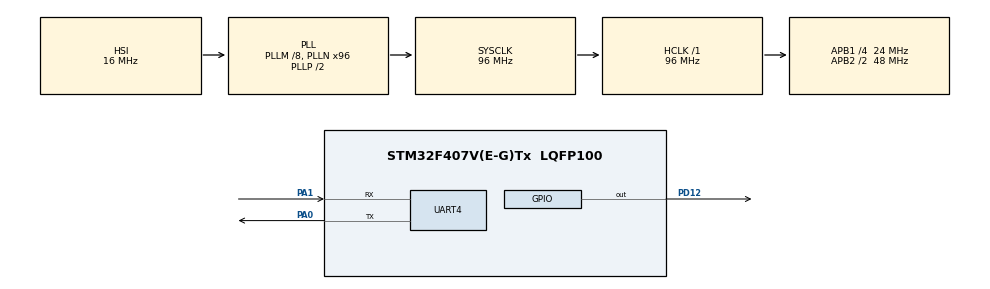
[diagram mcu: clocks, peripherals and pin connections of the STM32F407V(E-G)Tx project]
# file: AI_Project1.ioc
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Mcu.Family=STM32F4
Mcu.Name=STM32F407V(E-G)Tx
Mcu.Package=LQFP100
NVIC.PriorityGroup=NVIC_PRIORITYGROUP_4
PA0-WKUP.Mode=Asynchronous
PA0-WKUP.Signal=UART4_TX
PA1.Mode=Asynchronous
PA1.Signal=UART4_RX
PA13.Mode=Serial_Wire
PA13.Signal=SYS_JTMS-SWDIO
PA14.Mode=Serial_Wire
PA14.Signal=SYS_JTCK-SWCLK
PD12.Signal=GPIO_Output
ProjectManager.HeapSize=0x800
ProjectManager.StackSize=0x800
ProjectManager.TargetToolchain=STM32CubeIDE
RCC.48MHZClocksFreq_Value=48000000
RCC.AHBFreq_Value=96000000
RCC.APB1CLKDivider=RCC_HCLK_DIV4
RCC.APB1Freq_Value=24000000
RCC.APB1TimFreq_Value=48000000
RCC.APB2CLKDivider=RCC_HCLK_DIV2
RCC.APB2Freq_Value=48000000
RCC.APB2TimFreq_Value=96000000
RCC.CortexFreq_Value=96000000
RCC.HCLKFreq_Value=96000000
RCC.HSE_VALUE=25000000
RCC.HSI_VALUE=16000000
RCC.LSE_VALUE=32768
RCC.PLLM=8
RCC.PLLN=96
RCC.SYSCLKFreq_VALUE=96000000
RCC.SYSCLKSource=RCC_SYSCLKSOURCE_PLLCLK
RCC.VCOOutputFreq_Value=192000000
STMicroelectronics.X-CUBE-AI.10.2.0.ActivationBufferSizeList=2084
STMicroelectronics.X-CUBE-AI.10.2.0.ActivationBuffers=pool0
STMicroelectronics.X-CUBE-AI.10.2.0.ActivationNames=pool0
STMicroelectronics.X-CUBE-AI.10.2.0.ActivationSizes=AI_TEMP_CLASSIFIER_DATA_ACTIVATION_1_SIZE
STMicroelectronics.X-CUBE-AI.10.2.0.HeapSize=0x800
STMicroelectronics.X-CUBE-AI.10.2.0.InternalRamActivationBufferMaxSize=AI_TEMP_CLASSIFIER_DATA_ACTIVATIONS_SIZE
STMicroelectronics.X-CUBE-AI.10.2.0.LatestDirectoryUsed-0a6a85d186a75581f6178683ed5afddc2fad123f2e5eddf822d37d77b35d761b=C\:\\Users\\z665059\\OneDrive - ZF Friedrichshafen AG\\Documents\\my_project_temperature_classification\\notebooks
STMicroelectronics.X-CUBE-AI.10.2.0.MaximumNumberOfInputLayer=1
STMicroelectronics.X-CUBE-AI.10.2.0.MaximumNumberOfOutputLayer=1
STMicroelectronics.X-CUBE-AI.10.2.0.MaximumSizeOfInputLayer=1
STMicroelectronics.X-CUBE-AI.10.2.0.MaximumSizeOfOutputLayer=1
STMicroelectronics.X-CUBE-AI.10.2.0.ModelActualCompression-0a6a85d186a75581f6178683ed5afddc2fad123f2e5eddf822d37d77b35d761b=0.0
STMicroelectronics.X-CUBE-AI.10.2.0.ModelCompression-0a6a85d186a75581f6178683ed5afddc2fad123f2e5eddf822d37d77b35d761b=None
STMicroelectronics.X-CUBE-AI.10.2.0.ModelFlashOccupation-0a6a85d186a75581f6178683ed5afddc2fad123f2e5eddf822d37d77b35d761b=11472
STMicroelectronics.X-CUBE-AI.10.2.0.ModelHashList=0a6a85d186a75581f6178683ed5afddc2fad123f2e5eddf822d37d77b35d761b
STMicroelectronics.X-CUBE-AI.10.2.0.ModelKind-0a6a85d186a75581f6178683ed5afddc2fad123f2e5eddf822d37d77b35d761b=TFLITE
STMicroelectronics.X-CUBE-AI.10.2.0.ModelMacc-0a6a85d186a75581f6178683ed5afddc2fad123f2e5eddf822d37d77b35d761b=264
STMicroelectronics.X-CUBE-AI.10.2.0.ModelName-0a6a85d186a75581f6178683ed5afddc2fad123f2e5eddf822d37d77b35d761b=temp_classifier
STMicroelectronics.X-CUBE-AI.10.2.0.ModelNameList=temp_classifier
STMicroelectronics.X-CUBE-AI.10.2.0.ModelRamOccupation-0a6a85d186a75581f6178683ed5afddc2fad123f2e5eddf822d37d77b35d761b=2084
STMicroelectronics.X-CUBE-AI.10.2.0.ModelStructureFile-0a6a85d186a75581f6178683ed5afddc2fad123f2e5eddf822d37d77b35d761b=/C\:/Users/z665059/OneDrive - ZF Friedrichshafen AG/Documents/my_project_temperature_classification/notebooks/dht22_temp_classifier.tflite
STMicroelectronics.X-CUBE-AI.10.2.0.ModelType-0a6a85d186a75581f6178683ed5afddc2fad123f2e5eddf822d37d77b35d761b=STM32Cube.AI MCU runtime
STMicroelectronics.X-CUBE-AI.10.2.0.ReadyForCodeGeneration=true
STMicroelectronics.X-CUBE-AI.10.2.0.StackSize=0x800
STMicroelectronics.X-CUBE-AI.10.2.0.WorkingBufferStartAddrList=0xFFFFFFFF
STMicroelectronics.X-CUBE-AI.10.2.0.XAaCUBEAaAICcArtificialOoIntelligenceJjCore=true
STMicroelectronics.X-CUBE-AI.10.2.0.copyWeightToRam=false
STMicroelectronics.X-CUBE-AI.10.2.0.copyWeightToRam-0a6a85d186a75581f6178683ed5afddc2fad123f2e5eddf822d37d77b35d761b=false
STMicroelectronics.X-CUBE-AI.10.2.0.customLayerConfigEnabled=false
STMicroelectronics.X-CUBE-AI.10.2.0.customLayerConfigEnabled-0a6a85d186a75581f6178683ed5afddc2fad123f2e5eddf822d37d77b35d761b=false
STMicroelectronics.X-CUBE-AI.10.2.0.noOnnxIoTranspose=false
STMicroelectronics.X-CUBE-AI.10.2.0.noOnnxIoTranspose-0a6a85d186a75581f6178683ed5afddc2fad123f2e5eddf822d37d77b35d761b=false
STMicroelectronics.X-CUBE-AI.10.2.0.useInputAllocation=true
STMicroelectronics.X-CUBE-AI.10.2.0.useInputAllocation-0a6a85d186a75581f6178683ed5afddc2fad123f2e5eddf822d37d77b35d761b=true
STMicroelectronics.X-CUBE-AI.10.2.0.useOutputAllocation=true
STMicroelectronics.X-CUBE-AI.10.2.0.useOutputAllocation-0a6a85d186a75581f6178683ed5afddc2fad123f2e5eddf822d37d77b35d761b=true
TIM2.Period=65536
TIM2.Prescaler=96
UART4.VirtualMode=Asynchronous
VP_CRC_VS_CRC.Mode=CRC_Activate
VP_STMicroelectronics.X-CUBE-AI_VS_ArtificialOoIntelligenceJjXAaCUBEAaAI_10.2.0.Mode=ArtificialOoIntelligenceJjXAaCUBEAaAI
VP_TIM2_VS_ClockSourceINT.Mode=Internal
board=custom

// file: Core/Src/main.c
/* USER CODE BEGIN Header */
/**
  ******************************************************************************
  * @file           : main.c
  * @brief          : Main program body
  ******************************************************************************
  * @attention
  *
  * Copyright (c) 2026 STMicroelectronics.
  * All rights reserved.
  *
  * This software is licensed under terms that can be found in the LICENSE file
  * in the root directory of this software component.
  * If no LICENSE file comes with this software, it is provided AS-IS.
  *
  ******************************************************************************
  */
/* USER CODE END Header */
#include "main.h"

/* USER CODE BEGIN Includes */
#include <stdio.h>
#include <stdlib.h>
#include <time.h>
#include <string.h>

#include "ai_datatypes_defines.h"
#include "ai_platform.h"
#include "temp_classifier.h"
#include "temp_classifier_data.h"
/* USER CODE END Includes */

CRC_HandleTypeDef hcrc;

TIM_HandleTypeDef htim2;

UART_HandleTypeDef huart4;

/* USER CODE BEGIN PV */
/**
 * @brief Statically allocated buffers.
 * Buffers can be dynamically allocated using malloc and size information
 * given by the report in ai_network_get_report().
 */
// Chunk of memory used to hold intermediate values for neural network
ai_u8 activations[AI_TEMP_CLASSIFIER_DATA_ACTIVATIONS_SIZE];
// Buffers used to store input and output tensors
ai_u8 in_data[AI_TEMP_CLASSIFIER_IN_1_SIZE_BYTES];
ai_u8 out_data[AI_TEMP_CLASSIFIER_OUT_1_SIZE_BYTES];

/* AI buffer IO handlers */
// Initialize wrapper structs that hold pointers to data and info about the
  // data (tensor height, width, channels)
ai_buffer *ai_input;
ai_buffer *ai_output;
/* USER CODE END PV */

void SystemClock_Config(void);
static void MX_GPIO_Init(void);
static void MX_CRC_Init(void);
static void MX_TIM2_Init(void);
static void MX_UART4_Init(void);

int main(void)
{

  /* USER CODE BEGIN 1 */
	// Pointer to our model
	ai_handle temp_classifier = AI_HANDLE_NULL; //update network name from report
	ai_error err;
	ai_network_report report;
	//char buf[50];
	//int buf_len = 0;
	ai_i32 nbatch;
	uint32_t timestamp;
	float y_val;
	float temp_c = 15.0; //dht22_read_temperature();
	float temp_norm = temp_c / 50.0f;

  /* USER CODE END 1 */

  /* MCU Configuration--------------------------------------------------------*/

  /* Reset of all peripherals, Initializes the Flash interface and the Systick. */
  HAL_Init();

  /* Configure the system clock */
  SystemClock_Config();

  /* Initialize all configured peripherals */
  MX_GPIO_Init();
  MX_CRC_Init();
  MX_TIM2_Init();
  MX_UART4_Init();
  /* USER CODE BEGIN 2 */
  // Greetings!
     printf("\r\n\r\nSTM32 X-Cube-AI test\r\n");

  /** @brief Initialize network */
      const ai_handle acts[] = { activations };
      err = ai_temp_classifier_create_and_init(&temp_classifier, acts, NULL);
      if (err.type != AI_ERROR_NONE) {
          printf("ai init_and_create error\n");
          return -1;
      }

  /** @brief {optional} for debug/log purpose */
	  if (ai_temp_classifier_get_report(temp_classifier, &report) != true) {
		  printf("ai get report error\n");
		  return -1;
	  }

	  printf("Model name      : %s\n", report.model_name);
	  printf("Model signature : %s\n", report.model_signature);

	  ai_input = &report.inputs[0];
	  ai_output = &report.outputs[0];
	  printf("input[0] : (%ld, %ld, %ld)\n", AI_BUFFER_SHAPE_ELEM(ai_input, AI_SHAPE_HEIGHT),
										  AI_BUFFER_SHAPE_ELEM(ai_input, AI_SHAPE_WIDTH),
										  AI_BUFFER_SHAPE_ELEM(ai_input, AI_SHAPE_CHANNEL));
	  printf("output[0] : (%ld, %ld, %ld)\n", AI_BUFFER_SHAPE_ELEM(ai_output, AI_SHAPE_HEIGHT),
										   AI_BUFFER_SHAPE_ELEM(ai_output, AI_SHAPE_WIDTH),
										   AI_BUFFER_SHAPE_ELEM(ai_output, AI_SHAPE_CHANNEL));

	  // Set pointers wrapper structs to our data buffers
	  //ai_input[0].n_batches = 1; //n_batches = number of input samples processed in one inference call
	  //if >1    Process multiple samples together
	  ai_input[0].data = AI_HANDLE_PTR(in_data);
	  //ai_output[0].n_batches = 1;
	  ai_output[0].data = AI_HANDLE_PTR(out_data);

	  // Start timer/counter
	    HAL_TIM_Base_Start(&htim2);

  /* USER CODE END 2 */

  /* Infinite loop */
  /* USER CODE BEGIN WHILE */
  while (1)
  {
	/* Copy normalized value to AI input buffer */
	((ai_float *)in_data)[0] = (ai_float)temp_norm;

	// Get current timestamp
	 timestamp = htim2.Instance->CNT;

	 // Perform inference
	 nbatch = ai_temp_classifier_run(temp_classifier, &ai_input[0], &ai_output[0]);
	 if (nbatch != 1) {
		 err = ai_temp_classifier_get_error(temp_classifier);
		 printf("ai run error %d, %d\n", err.type, err.code);
		 return -1;
		 //buf_len = sprintf(buf, "Error: could not run inference\r\n");
		 //HAL_UART_Transmit(&huart4, (uint8_t *)buf, buf_len, 100);
	 }

	 /** @brief Post-process the output results/predictions */
	     printf("Inference output..\n");
	     for (int i = 0; i < AI_TEMP_CLASSIFIER_OUT_1_SIZE; i++) {
	         printf("%d,", out_data[i]);
	     }
	     printf("\n");
	     // Read output (predicted y) of neural network
	     y_val = ((float *)out_data)[0];

	     // Print output of neural network along with inference time (microseconds)
	     printf("Output: %f | Duration: %lu\r\n",y_val,htim2.Instance->CNT - timestamp);

	     // Wait before doing it again
	     HAL_Delay(500);

    /* USER CODE END WHILE */

  }
}

void SystemClock_Config(void)
{
  RCC_OscInitTypeDef RCC_OscInitStruct = {0};
  RCC_ClkInitTypeDef RCC_ClkInitStruct = {0};

  /** Configure the main internal regulator output voltage
  */
  __HAL_RCC_PWR_CLK_ENABLE();
  __HAL_PWR_VOLTAGESCALING_CONFIG(PWR_REGULATOR_VOLTAGE_SCALE1);

  /** Initializes the RCC Oscillators according to the specified parameters
  * in the RCC_OscInitTypeDef structure.
  */
  RCC_OscInitStruct.OscillatorType = RCC_OSCILLATORTYPE_HSI;
  RCC_OscInitStruct.HSIState = RCC_HSI_ON;
  RCC_OscInitStruct.HSICalibrationValue = RCC_HSICALIBRATION_DEFAULT;
  RCC_OscInitStruct.PLL.PLLState = RCC_PLL_ON;
  RCC_OscInitStruct.PLL.PLLSource = RCC_PLLSOURCE_HSI;
  RCC_OscInitStruct.PLL.PLLM = 8;
  RCC_OscInitStruct.PLL.PLLN = 96;
  RCC_OscInitStruct.PLL.PLLP = RCC_PLLP_DIV2;
  RCC_OscInitStruct.PLL.PLLQ = 4;
  if (HAL_RCC_OscConfig(&RCC_OscInitStruct) != HAL_OK)
  {
    Error_Handler();
  }

  /** Initializes the CPU, AHB and APB buses clocks
  */
  RCC_ClkInitStruct.ClockType = RCC_CLOCKTYPE_HCLK|RCC_CLOCKTYPE_SYSCLK
                              |RCC_CLOCKTYPE_PCLK1|RCC_CLOCKTYPE_PCLK2;
  RCC_ClkInitStruct.SYSCLKSource = RCC_SYSCLKSOURCE_PLLCLK;
  RCC_ClkInitStruct.AHBCLKDivider = RCC_SYSCLK_DIV1;
  RCC_ClkInitStruct.APB1CLKDivider = RCC_HCLK_DIV4;
  RCC_ClkInitStruct.APB2CLKDivider = RCC_HCLK_DIV2;

  if (HAL_RCC_ClockConfig(&RCC_ClkInitStruct, FLASH_LATENCY_3) != HAL_OK)
  {
    Error_Handler();
  }
}

static void MX_CRC_Init(void)
{

  hcrc.Instance = CRC;
  if (HAL_CRC_Init(&hcrc) != HAL_OK)
  {
    Error_Handler();
  }

}

static void MX_TIM2_Init(void)
{

  TIM_ClockConfigTypeDef sClockSourceConfig = {0};
  TIM_MasterConfigTypeDef sMasterConfig = {0};

  htim2.Instance = TIM2;
  htim2.Init.Prescaler = 96;
  htim2.Init.CounterMode = TIM_COUNTERMODE_UP;
  htim2.Init.Period = 65536;
  htim2.Init.ClockDivision = TIM_CLOCKDIVISION_DIV1;
  htim2.Init.AutoReloadPreload = TIM_AUTORELOAD_PRELOAD_DISABLE;
  if (HAL_TIM_Base_Init(&htim2) != HAL_OK)
  {
    Error_Handler();
  }
  sClockSourceConfig.ClockSource = TIM_CLOCKSOURCE_INTERNAL;
  if (HAL_TIM_ConfigClockSource(&htim2, &sClockSourceConfig) != HAL_OK)
  {
    Error_Handler();
  }
  sMasterConfig.MasterOutputTrigger = TIM_TRGO_RESET;
  sMasterConfig.MasterSlaveMode = TIM_MASTERSLAVEMODE_DISABLE;
  if (HAL_TIMEx_MasterConfigSynchronization(&htim2, &sMasterConfig) != HAL_OK)
  {
    Error_Handler();
  }

}

static void MX_UART4_Init(void)
{

  huart4.Instance = UART4;
  huart4.Init.BaudRate = 115200;
  huart4.Init.WordLength = UART_WORDLENGTH_8B;
  huart4.Init.StopBits = UART_STOPBITS_1;
  huart4.Init.Parity = UART_PARITY_NONE;
  huart4.Init.Mode = UART_MODE_TX_RX;
  huart4.Init.HwFlowCtl = UART_HWCONTROL_NONE;
  huart4.Init.OverSampling = UART_OVERSAMPLING_16;
  if (HAL_UART_Init(&huart4) != HAL_OK)
  {
    Error_Handler();
  }

}

static void MX_GPIO_Init(void)
{
  GPIO_InitTypeDef GPIO_InitStruct = {0};

  /* GPIO Ports Clock Enable */
  __HAL_RCC_GPIOA_CLK_ENABLE();
  __HAL_RCC_GPIOD_CLK_ENABLE();

  /*Configure GPIO pin Output Level */
  HAL_GPIO_WritePin(GPIOD, GPIO_PIN_12, GPIO_PIN_RESET);

  /*Configure GPIO pin : PD12 */
  GPIO_InitStruct.Pin = GPIO_PIN_12;
  GPIO_InitStruct.Mode = GPIO_MODE_OUTPUT_PP;
  GPIO_InitStruct.Pull = GPIO_NOPULL;
  GPIO_InitStruct.Speed = GPIO_SPEED_FREQ_LOW;
  HAL_GPIO_Init(GPIOD, &GPIO_InitStruct);

}

void Error_Handler(void)
{
  __disable_irq();
  while (1)
  {
  }
}
